AUTOSAR XML (schema 4-0-3)
package /ComponentTypes
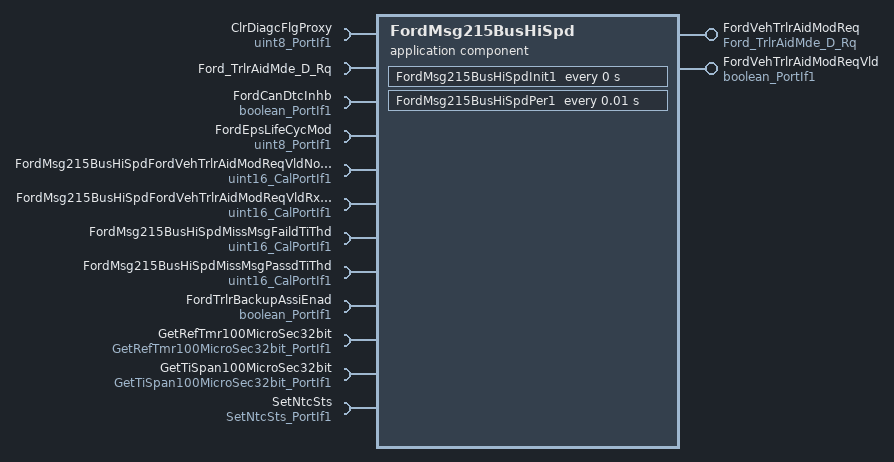
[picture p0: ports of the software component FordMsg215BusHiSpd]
  application sw component type FordMsg215BusHiSpd  # The purpose of the Ford Message 215 Bus High Speed function is to provide the Electric Power Steering system with Trailer Back up Assist and Gear Lever Position signals from CAN. The Ford Message 215 function will perform the missing message and signal invalid diagnostics as well as provide a validity signal for the signal values and received message
    provide port FordVehTrlrAidModReq: nonqueued-sender-com-spec{data-element=Ford_TrlrAidMde_D_Rq, init-value=0}, provided-interface=Ford_TrlrAidMde_D_Rq  # Customer datatype should be used. Datatype: Ford_TrlrAidMde_D_Rq. Elements are: 0 - "Cx0_NoRequest", 1 - "Cx1_Mode_1", 2 - "Cx2_Mode_2", 3 - "Cx3_Mode_3"
    provide port FordVehTrlrAidModReqVld: nonqueued-sender-com-spec{data-element=Logl, init-value=0}, provided-interface=boolean_PortIf1  # Used for Ford Vehicle Trailer Aid Mode Request Validity information.
    12 x require port:
      ClrDiagcFlgProxy: nonqueued-receiver-com-spec{data-element=Val, filter=data-filter-type=ALWAYS, init-value=0}, required-interface=uint8_PortIf1  # When ClrDiagcFlgProxy is True, Diagnostic test is performed.
      Ford_TrlrAidMde_D_Rq: nonqueued-receiver-com-spec{data-element=Ford_TrlrAidMde_D_Rq, filter=data-filter-type=ALWAYS, init-value=0}, required-interface=Ford_TrlrAidMde_D_Rq  # Customer datatype should be used. Datatype: Ford_TrlrAidMde_D_Rq. Elements are: 0 - "Cx0_NoRequest", 1 - "Cx1_Mode_1", 2 - "Cx2_Mode_2", 3 - "Cx3_Mode_3"
      FordCanDtcInhb: nonqueued-receiver-com-spec{data-element=Logl, filter=data-filter-type=ALWAYS, init-value=1}, required-interface=boolean_PortIf1  # When CAN DTC Inhibit is FALSE, Diagnostic test is performed
      FordEpsLifeCycMod: nonqueued-receiver-com-spec{data-element=Val, filter=data-filter-type=ALWAYS, init-value=0}, required-interface=uint8_PortIf1  # This signal is used to decide calibration value to FAIL the NTC
      FordMsg215BusHiSpdFordVehTrlrAidModReqVldNotRxdTiThd: parameter-require-com-spec{init-value=5000, parameter=Val}, required-interface=uint16_CalPortIf1  # Threshold to Reset the Missing message NTC
      FordMsg215BusHiSpdFordVehTrlrAidModReqVldRxdTiThd: parameter-require-com-spec{init-value=0, parameter=Val}, required-interface=uint16_CalPortIf1  # Threshold to set the Invalid message NTC
      FordMsg215BusHiSpdMissMsgFaildTiThd: parameter-require-com-spec{init-value=5000, parameter=Val}, required-interface=uint16_CalPortIf1  # Threshold to set the Missing message NTC
      FordMsg215BusHiSpdMissMsgPassdTiThd: parameter-require-com-spec{init-value=0, parameter=Val}, required-interface=uint16_CalPortIf1  # Threshold to Reset the Missing message NTC
      FordTrlrBackupAssiEnad: nonqueued-receiver-com-spec{data-element=Logl, filter=data-filter-type=ALWAYS, init-value=0}, required-interface=boolean_PortIf1  # Trailer Back Up Assist Enabled signal is a message signal which is received from CAN bus and which will be used for Diagnostics of received message
      GetRefTmr100MicroSec32bit: client-com-spec=Oper, required-interface=GetRefTmr100MicroSec32bit_PortIf1  # It captures simulation time from the SimnTi value obtained at root layer of model and gives the RefTmr.
      GetTiSpan100MicroSec32bit: client-com-spec=Oper, required-interface=GetTiSpan100MicroSec32bit_PortIf1  # It Captures simulation time from the SimnTi value, handles counter wrapping, and subtracts RefTmr, provides the TiSpan.
      SetNtcSts: client-com-spec=Oper, required-interface=SetNtcSts_PortIf1  # Set the NTC status
    behavior FordMsg215BusHiSpd_InternalBehavior
      ar-typed-per-instance-memorys:
        9 x data, all with sw-calibration-access=READ-ONLY:
          ClrDiagcFlgProxyPrev: type=uint8  # PIM used to store the previous value of CLear Diagnostic Flag Proxy signal.
          FirstTranVldFlg: type=boolean  # PIM used to identify whether the message is the first message or not.
          FordVehMsg215Miss: type=boolean  # PIM used to identify whether the message is missing or not.
          FordVehMsg215MissTmr: type=uint32  # PIM used to store the time related to missing message timer
          FordVehMsg215NotRxdRefTi: type=uint32  # PIM used to store the time related to not received message
          FordVehMsg215RxdRefTi: type=uint32  # PIM used to store the time related to received message.
          FordVehMsg215RxdTmr: type=uint32  # PIM used to store the time related to received message timer
          FordVehTrlrAidModReqPrev: type=Ford_TrlrAidMde_D_Rq  # PIM used to store the previous value of Ford Vehicle Trailer Aid Mode Request.
          FordVehTrlrAidModReqVldPrev: type=boolean  # PIM used to store the previous value of Ford Vehicle Trailer Aid Mode Request Valid.
      timing event FordMsg215BusHiSpd_InitEvent: start-on-event=FordMsg215BusHiSpdInit1, period=0
      timing event TMT_FordMsg215BusHiSpdPer1: start-on-event=FordMsg215BusHiSpdPer1, period=0.01
      runnable FordMsg215BusHiSpdInit1  # Initialization Runnable
        sync call SC_GetRefTmr100MicroSec32bit_Oper: operation=GetRefTmr100MicroSec32bit.Oper, timeout=0
      runnable FordMsg215BusHiSpdPer1  # Periodic runnable runnning at 0.01 second rate
        data-receive-point-by-arguments:
          5 x access:
            REC_ClrDiagcFlgProxy_Val: accessed-variable=ClrDiagcFlgProxy.Val
            REC_Ford_TrlrAidMde_D_Rq_Ford_TrlrAidMde_D_Rq: accessed-variable=Ford_TrlrAidMde_D_Rq.Ford_TrlrAidMde_D_Rq
            REC_FordCanDtcInhb_Logl: accessed-variable=FordCanDtcInhb.Logl
            REC_FordEpsLifeCycMod_Val: accessed-variable=FordEpsLifeCycMod.Val
            REC_FordTrlrBackupAssiEnad_Logl: accessed-variable=FordTrlrBackupAssiEnad.Logl
        data-send-points:
          access SEND_FordVehTrlrAidModReq_Ford_TrlrAidMde_D_Rq: accessed-variable=FordVehTrlrAidModReq.Ford_TrlrAidMde_D_Rq
          access SEND_FordVehTrlrAidModReqVld_Logl: accessed-variable=FordVehTrlrAidModReqVld.Logl
        sync call SC_GetRefTmr100MicroSec32bit_Oper: operation=GetRefTmr100MicroSec32bit.Oper, timeout=0
        sync call SC_GetTiSpan100MicroSec32bit_Oper: operation=GetTiSpan100MicroSec32bit.Oper, timeout=0
        sync call SC_SetNtcSts_Oper: operation=SetNtcSts.Oper, timeout=0
  swc implementation FordMsg215BusHiSpd_Implementation: behavior=FordMsg215BusHiSpd_InternalBehavior
    code-descriptors:
      code Default: artifact-descriptors=autosar-engineering-object={short-label=Default, category=SWSRC}
